AUTOSAR XML (schema 314)
package /ComponentType
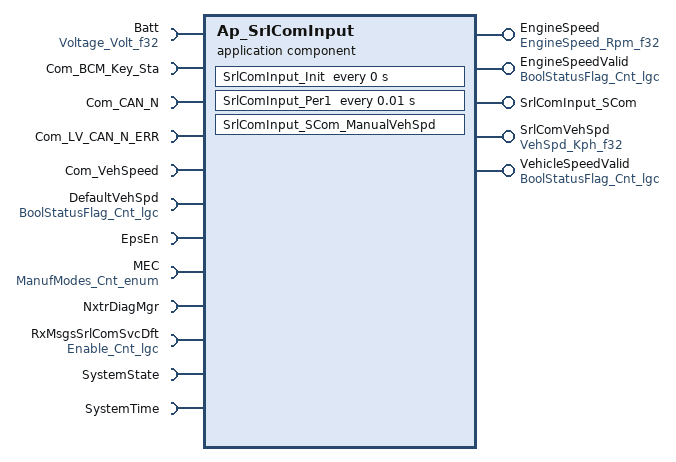
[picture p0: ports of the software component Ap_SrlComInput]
  application software component type Ap_SrlComInput
    5 x provide port:
      EngineSpeed: unqueued-sender-com-spec{data-element=Rpm_f32, can-invalidate=false, init-value=D_ZERO_ULS_F32}, provided-interface=EngineSpeed_Rpm_f32
      EngineSpeedValid: unqueued-sender-com-spec{data-element=Cnt_lgc, can-invalidate=false, init-value=D_FALSE_CNT_LGC}, provided-interface=BoolStatusFlag_Cnt_lgc
      SrlComInput_SCom: server-com-spec{operation=ManualVehSpd, queue-length=1}, provided-interface=SrlComInput_SCom
      SrlComVehSpd: unqueued-sender-com-spec{data-element=Kph_f32, can-invalidate=false, init-value=D_ZERO_ULS_F32}, provided-interface=VehSpd_Kph_f32
      VehicleSpeedValid: unqueued-sender-com-spec{data-element=Cnt_lgc, can-invalidate=false, init-value=D_FALSE_CNT_LGC}, provided-interface=BoolStatusFlag_Cnt_lgc
    12 x require port:
      Batt: unqueued-receiver-com-spec{data-element=Volt_f32, init-value=D_ZERO_ULS_F32}, required-interface=Voltage_Volt_f32
      Com_BCM_Key_Sta: unqueued-receiver-com-spec{data-element=Cnt_enum, init-value=C_BCM_Key_Sta}, required-interface=Com_BCM_Key_Sta
      Com_CAN_N: unqueued-receiver-com-spec{data-element=Cnt_u16, init-value=C_CAN_N}, required-interface=Com_CAN_N
      Com_LV_CAN_N_ERR: unqueued-receiver-com-spec{data-element=Cnt_lgc, init-value=C_LV_CAN_N_ERR}, required-interface=Com_LV_CAN_N_ERR
      Com_VehSpeed: unqueued-receiver-com-spec{data-element=Cnt_u16, init-value=C_VehSpeed}, required-interface=Com_VehSpeed
      DefaultVehSpd: unqueued-receiver-com-spec{data-element=Cnt_lgc, init-value=D_FALSE_CNT_LGC}, required-interface=BoolStatusFlag_Cnt_lgc
      EpsEn: client-com-spec=OP_GET, required-interface=EpsEn
      MEC: unqueued-receiver-com-spec{data-element=Cnt_enum, init-value=D_MANUFMODEINIT_CNT_ENUM}, required-interface=ManufModes_Cnt_enum
      NxtrDiagMgr: required-com-specs=[GetNTCActive, GetNTCFailed, GetNTCStatus, SetNTCStatus], required-interface=NxtrDiagMgr
      RxMsgsSrlComSvcDft: unqueued-receiver-com-spec{data-element=Cnt_lgc, init-value=D_FALSE_CNT_LGC}, required-interface=Enable_Cnt_lgc
      SystemState: required-interface=SystemState
      SystemTime: required-interface=SystemTime
        required-com-specs:
          DtrmnElapsedTime_mS_u16
          DtrmnElapsedTime_mS_u32
          DtrmnElapsedTime_uS_u16
          DtrmnElapsedTime_uS_u32
          GetSystemTime_mS_u32
          GetSystemTime_uS_u32
  internal behavior Ap_SrlComInput_InternalBehavior: component=Ap_SrlComInput
    timing event SrlComInput_InitEvent: start-on-event=SrlComInput_Init, period=0
    timing event TMT_SrlComInput_Per1: start-on-event=SrlComInput_Per1, period=0.01
    operation invoked event OIT_SrlComInput_SCom_ManualVehSpd_SrlComInput_SCom_ManualVehSpd: start-on-event=SrlComInput_SCom_ManualVehSpd, operation=SrlComInput_SCom.ManualVehSpd
    port-api-options:
      enable-take-address=false, indirect-api=false, port=Batt
      enable-take-address=false, indirect-api=false, port=Com_BCM_Key_Sta
      enable-take-address=false, indirect-api=false, port=Com_CAN_N
      enable-take-address=false, indirect-api=false, port=Com_LV_CAN_N_ERR
      enable-take-address=false, indirect-api=false, port=Com_VehSpeed
      enable-take-address=false, indirect-api=false, port=DefaultVehSpd
      enable-take-address=false, indirect-api=false, port=EngineSpeed
      enable-take-address=false, indirect-api=false, port=EngineSpeedValid
      enable-take-address=false, indirect-api=false, port=EpsEn
      enable-take-address=false, indirect-api=false, port=MEC
      enable-take-address=false, indirect-api=false, port=NxtrDiagMgr
      enable-take-address=false, indirect-api=false, port=RxMsgsSrlComSvcDft
      enable-take-address=false, indirect-api=false, port=SrlComInput_SCom
      enable-take-address=false, indirect-api=false, port=SrlComVehSpd
      enable-take-address=false, indirect-api=false, port=SystemState
      enable-take-address=false, indirect-api=false, port=SystemTime
      enable-take-address=false, indirect-api=false, port=VehicleSpeedValid
    runnable SrlComInput_Init
      data write access WRITE_EngineSpeedValid_Cnt_lgc: data-element=EngineSpeedValid.Cnt_lgc
      data write access WRITE_VehicleSpeedValid_Cnt_lgc: data-element=VehicleSpeedValid.Cnt_lgc
      sync call SC_NxtrDiagMgr_SetNTCStatus: operation=NxtrDiagMgr.SetNTCStatus, timeout=0
      sync call SC_SystemTime_GetSystemTime_mS_u32: operation=SystemTime.GetSystemTime_mS_u32, timeout=0
    runnable SrlComInput_Per1
      8 x data read access:
        READ_Batt_Volt_f32: data-element=Batt.Volt_f32
        READ_Com_BCM_Key_Sta_Cnt_enum: data-element=Com_BCM_Key_Sta.Cnt_enum
        READ_Com_CAN_N_Cnt_u16: data-element=Com_CAN_N.Cnt_u16
        READ_Com_LV_CAN_N_ERR_Cnt_lgc: data-element=Com_LV_CAN_N_ERR.Cnt_lgc
        READ_Com_VehSpeed_Cnt_u16: data-element=Com_VehSpeed.Cnt_u16
        READ_DefaultVehSpd_Cnt_lgc: data-element=DefaultVehSpd.Cnt_lgc
        READ_MEC_Cnt_enum: data-element=MEC.Cnt_enum
        READ_RxMsgsSrlComSvcDft_Cnt_lgc: data-element=RxMsgsSrlComSvcDft.Cnt_lgc
      4 x data write access:
        WRITE_EngineSpeed_Rpm_f32: data-element=EngineSpeed.Rpm_f32
        WRITE_EngineSpeedValid_Cnt_lgc: data-element=EngineSpeedValid.Cnt_lgc
        WRITE_SrlComVehSpd_Kph_f32: data-element=SrlComVehSpd.Kph_f32
        WRITE_VehicleSpeedValid_Cnt_lgc: data-element=VehicleSpeedValid.Cnt_lgc
      5 x sync call, all with timeout=0:
        SC_EpsEn_OP_GET: operation=EpsEn.OP_GET
        SC_NxtrDiagMgr_GetNTCFailed: operation=NxtrDiagMgr.GetNTCFailed
        SC_NxtrDiagMgr_SetNTCStatus: operation=NxtrDiagMgr.SetNTCStatus
        SC_SystemTime_DtrmnElapsedTime_mS_u16: operation=SystemTime.DtrmnElapsedTime_mS_u16
        SC_SystemTime_GetSystemTime_mS_u32: operation=SystemTime.GetSystemTime_mS_u32
    runnable SrlComInput_SCom_ManualVehSpd
  swc implementation Ap_SrlComInput_Implementation: behavior=Ap_SrlComInput_InternalBehavior
    code-descriptors:
      code Code: type=SRC
